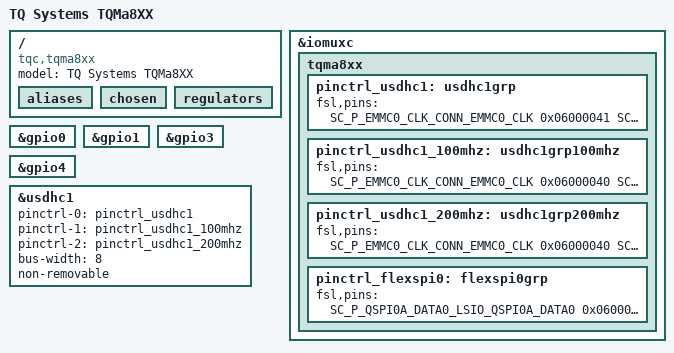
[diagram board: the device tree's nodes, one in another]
/*
 * Copyright 2017 NXP
 *
 * This program is free software; you can redistribute it and/or
 * modify it under the terms of the GNU General Public License
 * as published by the Free Software Foundation; either version 2
 * of the License, or (at your option) any later version.
 *
 * This program is distributed in the hope that it will be useful,
 * but WITHOUT ANY WARRANTY; without even the implied warranty of
 * MERCHANTABILITY or FITNESS FOR A PARTICULAR PURPOSE.  See the
 * GNU General Public License for more details.
 */

#include "fsl-imx8qxp.dtsi"

/ {
	model = "TQ Systems TQMa8XX";
	compatible = "tqc,tqma8xx", "fsl,imx8qxp";

	aliases {
	};

	chosen {
	};

	regulators {
	};
};

&iomuxc {
	pinctrl-names = "default";
	tqma8xx {
		pinctrl_usdhc1: usdhc1grp {
			fsl,pins = <
				SC_P_EMMC0_CLK_CONN_EMMC0_CLK		0x06000041
				SC_P_EMMC0_CMD_CONN_EMMC0_CMD		0x00000021
				SC_P_EMMC0_DATA0_CONN_EMMC0_DATA0	0x00000021
				SC_P_EMMC0_DATA1_CONN_EMMC0_DATA1	0x00000021
				SC_P_EMMC0_DATA2_CONN_EMMC0_DATA2	0x00000021
				SC_P_EMMC0_DATA3_CONN_EMMC0_DATA3	0x00000021
				SC_P_EMMC0_DATA4_CONN_EMMC0_DATA4	0x00000021
				SC_P_EMMC0_DATA5_CONN_EMMC0_DATA5	0x00000021
				SC_P_EMMC0_DATA6_CONN_EMMC0_DATA6	0x00000021
				SC_P_EMMC0_DATA7_CONN_EMMC0_DATA7	0x00000021
				SC_P_EMMC0_STROBE_CONN_EMMC0_STROBE	0x06000041
			>;
		};

		pinctrl_usdhc1_100mhz: usdhc1grp100mhz {
			fsl,pins = <
				SC_P_EMMC0_CLK_CONN_EMMC0_CLK		0x06000040
				SC_P_EMMC0_CMD_CONN_EMMC0_CMD		0x00000020
				SC_P_EMMC0_DATA0_CONN_EMMC0_DATA0	0x00000020
				SC_P_EMMC0_DATA1_CONN_EMMC0_DATA1	0x00000020
				SC_P_EMMC0_DATA2_CONN_EMMC0_DATA2	0x00000020
				SC_P_EMMC0_DATA3_CONN_EMMC0_DATA3	0x00000020
				SC_P_EMMC0_DATA4_CONN_EMMC0_DATA4	0x00000020
				SC_P_EMMC0_DATA5_CONN_EMMC0_DATA5	0x00000020
				SC_P_EMMC0_DATA6_CONN_EMMC0_DATA6	0x00000020
				SC_P_EMMC0_DATA7_CONN_EMMC0_DATA7	0x00000020
				SC_P_EMMC0_STROBE_CONN_EMMC0_STROBE	0x06000040
			>;
		};

		pinctrl_usdhc1_200mhz: usdhc1grp200mhz {
			fsl,pins = <
				SC_P_EMMC0_CLK_CONN_EMMC0_CLK		0x06000040
				SC_P_EMMC0_CMD_CONN_EMMC0_CMD		0x00000020
				SC_P_EMMC0_DATA0_CONN_EMMC0_DATA0	0x00000020
				SC_P_EMMC0_DATA1_CONN_EMMC0_DATA1	0x00000020
				SC_P_EMMC0_DATA2_CONN_EMMC0_DATA2	0x00000020
				SC_P_EMMC0_DATA3_CONN_EMMC0_DATA3	0x00000020
				SC_P_EMMC0_DATA4_CONN_EMMC0_DATA4	0x00000020
				SC_P_EMMC0_DATA5_CONN_EMMC0_DATA5	0x00000020
				SC_P_EMMC0_DATA6_CONN_EMMC0_DATA6	0x00000020
				SC_P_EMMC0_DATA7_CONN_EMMC0_DATA7	0x00000020
				SC_P_EMMC0_STROBE_CONN_EMMC0_STROBE	0x06000040
			>;
		};

		pinctrl_flexspi0: flexspi0grp {
			fsl,pins = <
				SC_P_QSPI0A_DATA0_LSIO_QSPI0A_DATA0	0x0600004c
				SC_P_QSPI0A_DATA1_LSIO_QSPI0A_DATA1	0x0600004c
				SC_P_QSPI0A_DATA2_LSIO_QSPI0A_DATA2	0x0600004c
				SC_P_QSPI0A_DATA3_LSIO_QSPI0A_DATA3	0x0600004c
				SC_P_QSPI0A_DQS_LSIO_QSPI0A_DQS		0x0600004c
				SC_P_QSPI0A_SS0_B_LSIO_QSPI0A_SS0_B	0x0600004c
				SC_P_QSPI0A_SS1_B_LSIO_QSPI0A_SS1_B	0x0600004c
				SC_P_QSPI0A_SCLK_LSIO_QSPI0A_SCLK	0x0600004c
				SC_P_QSPI0B_SCLK_LSIO_QSPI0B_SCLK	0x0600004c
				SC_P_QSPI0B_DATA0_LSIO_QSPI0B_DATA0	0x0600004c
				SC_P_QSPI0B_DATA1_LSIO_QSPI0B_DATA1	0x0600004c
				SC_P_QSPI0B_DATA2_LSIO_QSPI0B_DATA2	0x0600004c
				SC_P_QSPI0B_DATA3_LSIO_QSPI0B_DATA3	0x0600004c
				SC_P_QSPI0B_DQS_LSIO_QSPI0B_DQS		0x0600004c
				SC_P_QSPI0B_SS0_B_LSIO_QSPI0B_SS0_B	0x0600004c
				SC_P_QSPI0B_SS1_B_LSIO_QSPI0B_SS1_B	0x0600004c
			>;
		};
	};
};

&gpio0 {
	status = "okay";
};

&gpio1 {
	status = "okay";
};

&gpio3 {
	status = "okay";
};

&gpio4 {
	status = "okay";
};

&usdhc1 {
	pinctrl-names = "default", "state_100mhz", "state_200mhz";
	pinctrl-0 = <&pinctrl_usdhc1>;
	pinctrl-1 = <&pinctrl_usdhc1_100mhz>;
	pinctrl-2 = <&pinctrl_usdhc1_200mhz>;
	bus-width = <8>;
	non-removable;
	status = "okay";
};

